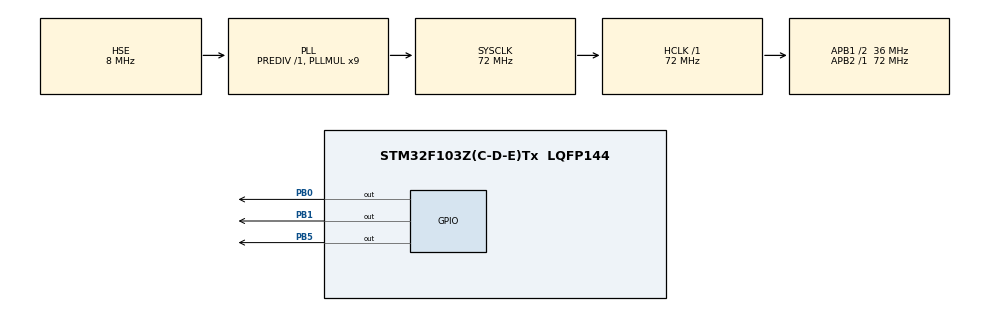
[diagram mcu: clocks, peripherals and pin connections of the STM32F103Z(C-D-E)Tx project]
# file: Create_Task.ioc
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FREERTOS.Tasks01=LEDTask01,0,128,StartTask01,Default,NULL,Dynamic,NULL,NULL;LEDTask02,-3,128,StartTask02,Default,NULL,Dynamic,NULL,NULL;LEDTask03,-3,128,StartTask03,Default,NULL,Dynamic,NULL,NULL
Mcu.Family=STM32F1
Mcu.Name=STM32F103Z(C-D-E)Tx
Mcu.Package=LQFP144
NVIC.PriorityGroup=NVIC_PRIORITYGROUP_4
NVIC.TIM1_UP_IRQn=true\:15\:0\:false\:false\:true\:false\:false\:true
NVIC.TimeBase=TIM1_UP_IRQn
NVIC.TimeBaseIP=TIM1
OSC_IN.Mode=HSE-External-Oscillator
OSC_IN.Signal=RCC_OSC_IN
OSC_OUT.Mode=HSE-External-Oscillator
OSC_OUT.Signal=RCC_OSC_OUT
PB0.Signal=GPIO_Output
PB1.Signal=GPIO_Output
PB5.Signal=GPIO_Output
ProjectManager.HeapSize=0x200
ProjectManager.StackSize=0x400
ProjectManager.TargetToolchain=MDK-ARM V5.32
RCC.AHBFreq_Value=72000000
RCC.APB1CLKDivider=RCC_HCLK_DIV2
RCC.APB1Freq_Value=36000000
RCC.APB1TimFreq_Value=72000000
RCC.APB2Freq_Value=72000000
RCC.APB2TimFreq_Value=72000000
RCC.HCLKFreq_Value=72000000
RCC.PLLMUL=RCC_PLL_MUL9
RCC.PLLSourceVirtual=RCC_PLLSOURCE_HSE
RCC.SYSCLKFreq_VALUE=72000000
RCC.SYSCLKSource=RCC_SYSCLKSOURCE_PLLCLK
RCC.USBFreq_Value=72000000
VP_FREERTOS_VS_CMSIS_V1.Mode=CMSIS_V1
VP_SYS_VS_ND.Mode=No_Debug
VP_SYS_VS_tim1.Mode=TIM1
board=custom

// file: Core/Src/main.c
/* USER CODE BEGIN Header */
/**
  ******************************************************************************
  * @file           : main.c
  * @brief          : Main program body
  ******************************************************************************
  * @attention
  *
  * <h2><center>&copy; Copyright (c) 2021 STMicroelectronics.
  * All rights reserved.</center></h2>
  *
  * This software component is licensed by ST under Ultimate Liberty license
  * SLA0044, the "License"; You may not use this file except in compliance with
  * the License. You may obtain a copy of the License at:
  *                             www.st.com/SLA0044
  *
  ******************************************************************************
  */
/* USER CODE END Header */
#include "main.h"
#include "cmsis_os.h"

osThreadId LEDTask01Handle;
osThreadId LEDTask02Handle;
osThreadId LEDTask03Handle;

void SystemClock_Config(void);
static void MX_GPIO_Init(void);
void StartTask01(void const * argument);
void StartTask02(void const * argument);
void StartTask03(void const * argument);

int main(void)
{

  /* MCU Configuration--------------------------------------------------------*/

  /* Reset of all peripherals, Initializes the Flash interface and the Systick. */
  HAL_Init();

  /* Configure the system clock */
  SystemClock_Config();

  /* Initialize all configured peripherals */
  MX_GPIO_Init();

  /* Create the thread(s) */
  /* definition and creation of LEDTask01 */
  osThreadDef(LEDTask01, StartTask01, osPriorityNormal, 0, 128);
  LEDTask01Handle = osThreadCreate(osThread(LEDTask01), NULL);

  /* definition and creation of LEDTask02 */
  osThreadDef(LEDTask02, StartTask02, osPriorityIdle, 0, 128);
  LEDTask02Handle = osThreadCreate(osThread(LEDTask02), NULL);

  /* definition and creation of LEDTask03 */
  osThreadDef(LEDTask03, StartTask03, osPriorityIdle, 0, 128);
  LEDTask03Handle = osThreadCreate(osThread(LEDTask03), NULL);

  /* Start scheduler */
  osKernelStart();

  /* We should never get here as control is now taken by the scheduler */
  /* Infinite loop */
  while (1)
  {

  }
}

void SystemClock_Config(void)
{
  RCC_OscInitTypeDef RCC_OscInitStruct = {0};
  RCC_ClkInitTypeDef RCC_ClkInitStruct = {0};

  /** Initializes the RCC Oscillators according to the specified parameters
  * in the RCC_OscInitTypeDef structure.
  */
  RCC_OscInitStruct.OscillatorType = RCC_OSCILLATORTYPE_HSE;
  RCC_OscInitStruct.HSEState = RCC_HSE_ON;
  RCC_OscInitStruct.HSEPredivValue = RCC_HSE_PREDIV_DIV1;
  RCC_OscInitStruct.HSIState = RCC_HSI_ON;
  RCC_OscInitStruct.PLL.PLLState = RCC_PLL_ON;
  RCC_OscInitStruct.PLL.PLLSource = RCC_PLLSOURCE_HSE;
  RCC_OscInitStruct.PLL.PLLMUL = RCC_PLL_MUL9;
  if (HAL_RCC_OscConfig(&RCC_OscInitStruct) != HAL_OK)
  {
    Error_Handler();
  }
  /** Initializes the CPU, AHB and APB buses clocks
  */
  RCC_ClkInitStruct.ClockType = RCC_CLOCKTYPE_HCLK|RCC_CLOCKTYPE_SYSCLK
                              |RCC_CLOCKTYPE_PCLK1|RCC_CLOCKTYPE_PCLK2;
  RCC_ClkInitStruct.SYSCLKSource = RCC_SYSCLKSOURCE_PLLCLK;
  RCC_ClkInitStruct.AHBCLKDivider = RCC_SYSCLK_DIV1;
  RCC_ClkInitStruct.APB1CLKDivider = RCC_HCLK_DIV2;
  RCC_ClkInitStruct.APB2CLKDivider = RCC_HCLK_DIV1;

  if (HAL_RCC_ClockConfig(&RCC_ClkInitStruct, FLASH_LATENCY_2) != HAL_OK)
  {
    Error_Handler();
  }
}

static void MX_GPIO_Init(void)
{
  GPIO_InitTypeDef GPIO_InitStruct = {0};

  /* GPIO Ports Clock Enable */
  __HAL_RCC_GPIOB_CLK_ENABLE();

  /*Configure GPIO pin Output Level */
  HAL_GPIO_WritePin(GPIOB, GPIO_PIN_0|GPIO_PIN_1|GPIO_PIN_5, GPIO_PIN_RESET);

  /*Configure GPIO pins : PB0 PB1 PB5 */
  GPIO_InitStruct.Pin = GPIO_PIN_0|GPIO_PIN_1|GPIO_PIN_5;
  GPIO_InitStruct.Mode = GPIO_MODE_OUTPUT_PP;
  GPIO_InitStruct.Pull = GPIO_NOPULL;
  GPIO_InitStruct.Speed = GPIO_SPEED_FREQ_LOW;
  HAL_GPIO_Init(GPIOB, &GPIO_InitStruct);

}

void StartTask01(void const * argument)
{
  /* USER CODE BEGIN 5 */
  /* Infinite loop */
  for(;;)
  {

	  HAL_GPIO_WritePin(GPIOB, GPIO_PIN_0,GPIO_PIN_SET);
    osDelay(5);
	  HAL_GPIO_WritePin(GPIOB, GPIO_PIN_0,GPIO_PIN_RESET);
		osDelay(5);
  }
  /* USER CODE END 5 */
}

void StartTask02(void const * argument)
{
  /* USER CODE BEGIN StartTask02 */
  /* Infinite loop */
  for(;;)
  {
	  HAL_GPIO_WritePin(GPIOB, GPIO_PIN_1,GPIO_PIN_SET);
    osDelay(50);
	  HAL_GPIO_WritePin(GPIOB, GPIO_PIN_1,GPIO_PIN_RESET);
		osDelay(50);
  }
  /* USER CODE END StartTask02 */
}

void StartTask03(void const * argument)
{
  /* USER CODE BEGIN StartTask03 */
  /* Infinite loop */
  for(;;)
  {
	  HAL_GPIO_WritePin(GPIOB, GPIO_PIN_5,GPIO_PIN_SET);
    osDelay(500);
	  HAL_GPIO_WritePin(GPIOB, GPIO_PIN_5,GPIO_PIN_RESET);
		osDelay(500);
  }
  /* USER CODE END StartTask03 */
}

void HAL_TIM_PeriodElapsedCallback(TIM_HandleTypeDef *htim)
{
  if (htim->Instance == TIM1) {
    HAL_IncTick();
  }
}

void Error_Handler(void)
{
  __disable_irq();
  while (1)
  {
  }
}

/************************ (C) COPYRIGHT STMicroelectronics *****END OF FILE****/
